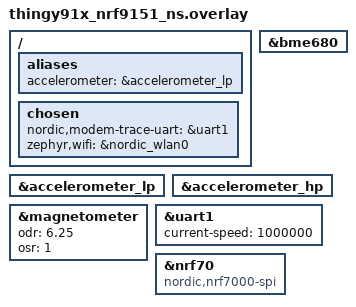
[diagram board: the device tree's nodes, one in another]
/*
 * Copyright (c) 2024 Nordic Semiconductor ASA
 *
 * SPDX-License-Identifier: LicenseRef-Nordic-5-Clause
 */

#include <thingy91x_wifi.dtsi>

&bme680 {
	status = "okay";
};
&accelerometer_lp {
	status = "okay";
};

/* Second accelerometer plus gyroscope (BMI270). Log-only for now, see CONFIG_APP_BMI270_LOG. */
&accelerometer_hp {
	status = "okay";
};

/* Magnetometer for the compass. Low rate and no oversampling to save power. */
&magnetometer {
	status = "okay";
	odr = "6.25";
	osr = <1>;
};

/ {
	aliases {
		accelerometer = &accelerometer_lp;
	};
};
/ {
	chosen {
		nordic,modem-trace-uart = &uart1;
		zephyr,wifi = &nordic_wlan0;
	};
};

&uart1 {
	status = "okay";
	current-speed = <1000000>;
};

/* Switch to nrf7000 emulation so that scan-only mode is used. */
&nrf70 {
	compatible = "nordic,nrf7000-spi";
};


/* Flash partitions (littlefs_storage, MCUboot slots, etc.) */
/delete-node/ &b0_partition;
/delete-node/ &s0_partition;
/delete-node/ &s1_partition;
/delete-node/ &external_flash_partition;
#include "att_flash_partitions.dtsi"
#include "att_sram_partitions.dtsi"
